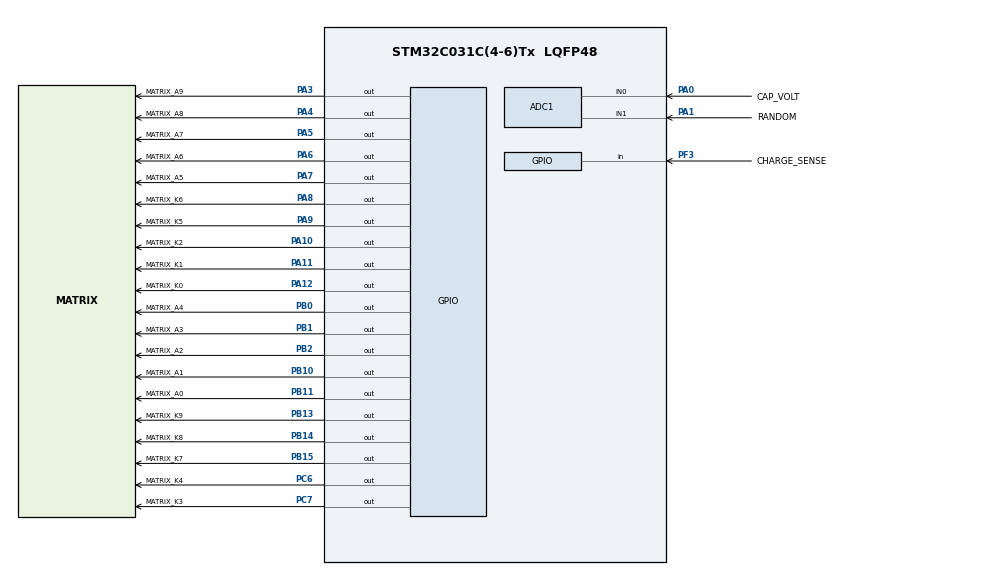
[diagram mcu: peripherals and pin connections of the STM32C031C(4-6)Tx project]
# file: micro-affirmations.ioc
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ADC1.EOCSelection=ADC_EOC_SINGLE_CONV
ADC1.NbrOfConversionFlag=0
ADC1.SelectedChannel=ADC_CHANNEL_0|ADC_CHANNEL_1
ADC1.master=1
Dma.ADC1.0.Direction=DMA_PERIPH_TO_MEMORY
Dma.ADC1.0.EventEnable=DISABLE
Dma.ADC1.0.Instance=DMA1_Channel1
Dma.ADC1.0.MemDataAlignment=DMA_MDATAALIGN_HALFWORD
Dma.ADC1.0.MemInc=DMA_MINC_ENABLE
Dma.ADC1.0.Mode=DMA_NORMAL
Dma.ADC1.0.PeriphDataAlignment=DMA_PDATAALIGN_HALFWORD
Dma.ADC1.0.PeriphInc=DMA_PINC_DISABLE
Dma.ADC1.0.Polarity=HAL_DMAMUX_REQ_GEN_RISING
Dma.ADC1.0.Priority=DMA_PRIORITY_LOW
Dma.ADC1.0.RequestNumber=1
Dma.ADC1.0.SignalID=NONE
Dma.ADC1.0.SyncEnable=DISABLE
Dma.ADC1.0.SyncPolarity=HAL_DMAMUX_SYNC_NO_EVENT
Dma.ADC1.0.SyncRequestNumber=1
Dma.ADC1.0.SyncSignalID=NONE
Dma.Request0=ADC1
Mcu.Family=STM32C0
Mcu.Name=STM32C031C(4-6)Tx
Mcu.Package=LQFP48
NVIC.DMA1_Channel1_IRQn=true\:0\:0\:false\:false\:true\:false\:true\:true
NVIC.TIM3_IRQn=true\:0\:0\:false\:false\:true\:true\:true\:true
PA0.GPIO_Label=CAP_VOLT
PA0.Mode=IN0
PA0.Signal=ADC1_IN0
PA1.GPIO_Label=RANDOM
PA1.Mode=IN1
PA1.Signal=ADC1_IN1
PA10.GPIO_Label=MATRIX_K2
PA10.Signal=GPIO_Output
PA11\ [PA9].GPIO_Label=MATRIX_K1
PA11\ [PA9].Signal=GPIO_Output
PA12\ [PA10].GPIO_Label=MATRIX_K0
PA12\ [PA10].Signal=GPIO_Output
PA13.Mode=Serial_Wire
PA13.Signal=DEBUG_SWDIO
PA14-BOOT0.Mode=Serial_Wire
PA14-BOOT0.Signal=DEBUG_SWCLK
PA3.GPIO_Label=MATRIX_A9
PA3.Signal=GPIO_Output
PA4.GPIO_Label=MATRIX_A8
PA4.Signal=GPIO_Output
PA5.GPIO_Label=MATRIX_A7
PA5.Signal=GPIO_Output
PA6.GPIO_Label=MATRIX_A6
PA6.Signal=GPIO_Output
PA7.GPIO_Label=MATRIX_A5
PA7.Signal=GPIO_Output
PA8.GPIO_Label=MATRIX_K6
PA8.Signal=GPIO_Output
PA9.GPIO_Label=MATRIX_K5
PA9.Signal=GPIO_Output
PB0.GPIO_Label=MATRIX_A4
PB0.Signal=GPIO_Output
PB1.GPIO_Label=MATRIX_A3
PB1.Signal=GPIO_Output
PB10.GPIO_Label=MATRIX_A1
PB10.Signal=GPIO_Output
PB11.GPIO_Label=MATRIX_A0
PB11.Signal=GPIO_Output
PB13.GPIO_Label=MATRIX_K9
PB13.Signal=GPIO_Output
PB14.GPIO_Label=MATRIX_K8
PB14.Signal=GPIO_Output
PB15.GPIO_Label=MATRIX_K7
PB15.Signal=GPIO_Output
PB2.GPIO_Label=MATRIX_A2
PB2.Signal=GPIO_Output
PC6.GPIO_Label=MATRIX_K4
PC6.Signal=GPIO_Output
PC7.GPIO_Label=MATRIX_K3
PC7.Signal=GPIO_Output
PF3.GPIO_Label=CHARGE_SENSE
PF3.Signal=GPIO_Input
ProjectManager.HeapSize=0x200
ProjectManager.StackSize=0x400
ProjectManager.TargetToolchain=Makefile
RCC.ADCFreq_Value=48000000
RCC.AHBFreq_Value=48000000
RCC.CortexFreq_Value=48000000
RCC.EXTERNAL_CLOCK_VALUE=12288000
RCC.HCLKFreq_Value=48000000
RCC.HSE_VALUE=8000000
RCC.HSISYSCLKDivider=RCC_HSI_DIV1
RCC.HSI_VALUE=48000000
RCC.LSE_VALUE=32768
RCC.SYSCLKFreq_VALUE=48000000
TIM3.AutoReloadPreload=TIM_AUTORELOAD_PRELOAD_ENABLE
TIM3.Period=999
TIM3.Prescaler=47
VP_TIM3_VS_ClockSourceINT.Mode=Internal
board=custom

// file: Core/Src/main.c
/* USER CODE BEGIN Header */
/**
  ******************************************************************************
  * @file           : main.c
  * @brief          : Main program body
  ******************************************************************************
  * @attention
  *
  * Copyright (c) 2026 STMicroelectronics.
  * All rights reserved.
  *
  * This software is licensed under terms that can be found in the LICENSE file
  * in the root directory of this software component.
  * If no LICENSE file comes with this software, it is provided AS-IS.
  *
  ******************************************************************************
  */
/* USER CODE END Header */
#include "main.h"
#include "adc.h"
#include "dma.h"
#include "tim.h"
#include "gpio.h"

/* USER CODE BEGIN Includes */
#include "app.h"
/* USER CODE END Includes */

void SystemClock_Config(void);

int main(void)
{

  /* MCU Configuration--------------------------------------------------------*/

  /* Reset of all peripherals, Initializes the Flash interface and the Systick. */
  HAL_Init();

  /* Configure the system clock */
  SystemClock_Config();

  /* Initialize all configured peripherals */
  MX_GPIO_Init();
  MX_DMA_Init();
  MX_ADC1_Init();
  MX_TIM3_Init();
  /* USER CODE BEGIN 2 */
  HAL_TIM_Base_Start_IT(&htim3);
  /* USER CODE END 2 */

  /* Infinite loop */
  /* USER CODE BEGIN WHILE */
  while (1)
  {
    app_main();
    /* USER CODE END WHILE */

  }
}

void SystemClock_Config(void)
{
  RCC_OscInitTypeDef RCC_OscInitStruct = {0};
  RCC_ClkInitTypeDef RCC_ClkInitStruct = {0};

  __HAL_FLASH_SET_LATENCY(FLASH_LATENCY_1);

  /** Initializes the RCC Oscillators according to the specified parameters
  * in the RCC_OscInitTypeDef structure.
  */
  RCC_OscInitStruct.OscillatorType = RCC_OSCILLATORTYPE_HSI;
  RCC_OscInitStruct.HSIState = RCC_HSI_ON;
  RCC_OscInitStruct.HSIDiv = RCC_HSI_DIV1;
  RCC_OscInitStruct.HSICalibrationValue = RCC_HSICALIBRATION_DEFAULT;
  if (HAL_RCC_OscConfig(&RCC_OscInitStruct) != HAL_OK)
  {
    Error_Handler();
  }

  /** Initializes the CPU, AHB and APB buses clocks
  */
  RCC_ClkInitStruct.ClockType = RCC_CLOCKTYPE_HCLK|RCC_CLOCKTYPE_SYSCLK
                              |RCC_CLOCKTYPE_PCLK1;
  RCC_ClkInitStruct.SYSCLKSource = RCC_SYSCLKSOURCE_HSI;
  RCC_ClkInitStruct.SYSCLKDivider = RCC_SYSCLK_DIV1;
  RCC_ClkInitStruct.AHBCLKDivider = RCC_HCLK_DIV1;
  RCC_ClkInitStruct.APB1CLKDivider = RCC_APB1_DIV1;

  if (HAL_RCC_ClockConfig(&RCC_ClkInitStruct, FLASH_LATENCY_1) != HAL_OK)
  {
    Error_Handler();
  }
}

/* USER CODE BEGIN 4 */
void HAL_TIM_PeriodElapsedCallback(TIM_HandleTypeDef *htim) {
    if(htim->Instance == TIM3) {
        app_updateMultiplex();
    }
}
/* USER CODE END 4 */

void Error_Handler(void)
{
  __disable_irq();
  while (1)
  {
  }
}
